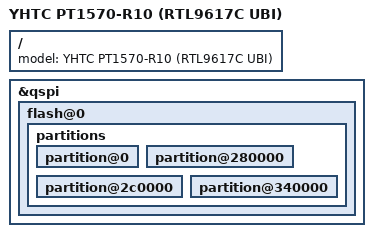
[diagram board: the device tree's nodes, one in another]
// SPDX-License-Identifier: GPL-2.0-only
#include "rtl9617c-tyfza1-pcie.dts"
#include "rtl9617c-tyfza1-usb.dtsi"

/* Model is what /tmp/sysinfo/model and the LuCI board name show. This
 * branch targets PT1570-R10 only, so do not advertise it as TYFZA1.
 * The compatible string stays "tianyi,tyfza1": the drivers match on it,
 * and the UBI volume IDs (ubi0_3/ubi0_6 vs ubi0_4/ubi0_7) are what
 * actually tell the two boards apart at upgrade time. */
/ { model = "YHTC PT1570-R10 (RTL9617C UBI)"; };

&qspi {
	flash@0 {
		/delete-property/ read-only;
		partitions {
			partition@0 { /delete-property/ read-only; };
			partition@280000 { /delete-property/ read-only; };
			partition@2c0000 { /delete-property/ read-only; };
			partition@340000 { /delete-property/ read-only; };
		};
	};
};
